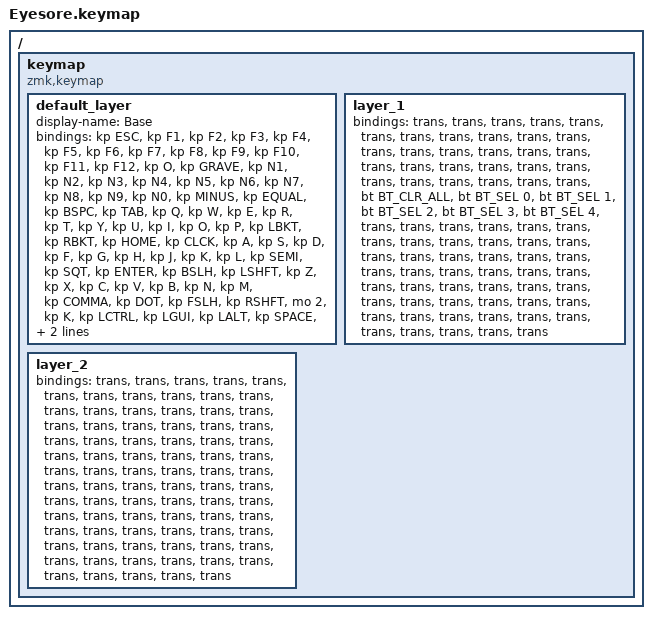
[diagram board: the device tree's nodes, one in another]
#include <behaviors.dtsi>
#include <dt-bindings/zmk/bt.h>
#include <dt-bindings/zmk/keys.h>

/ {
    keymap {
        compatible = "zmk,keymap";

        default_layer {
            display-name = "Base";
            bindings = <
&kp ESC  &kp F1  &kp F2  &kp F3  &kp F4  &kp F5  &kp F6  &kp F7  &kp F8  &kp F9  &kp F10  &kp F11  &kp F12  &kp O  &kp GRAVE  &kp N1  &kp N2  &kp N3  &kp N4  &kp N5  &kp N6  &kp N7  &kp N8  &kp N9  &kp N0  &kp MINUS  &kp EQUAL  &kp BSPC  &kp TAB  &kp Q  &kp W  &kp E  &kp R  &kp T  &kp Y  &kp U  &kp I  &kp O  &kp P  &kp LBKT  &kp RBKT  &kp HOME  &kp CLCK  &kp A  &kp S  &kp D  &kp F  &kp G  &kp H  &kp J  &kp K  &kp L  &kp SEMI  &kp SQT  &kp ENTER  &kp BSLH  &kp LSHFT  &kp Z  &kp X  &kp C  &kp V  &kp B  &kp N  &kp M  &kp COMMA  &kp DOT  &kp FSLH  &kp RSHFT  &mo 2  &kp K  &kp LCTRL  &kp LGUI  &kp LALT  &kp SPACE  &kp RALT  &kp Y  &kp RCTRL  &kp LEFT  &kp DOWN  &kp UP  &kp RIGHT  &mo 1
            >;
        };

        layer_1 {
            bindings = <
&trans  &trans  &trans  &trans  &trans  &trans  &trans  &trans  &trans  &trans  &trans  &trans  &trans  &trans  &trans  &trans  &trans  &trans  &trans  &trans  &trans  &trans  &trans  &trans  &trans  &trans  &trans  &trans  &trans  &bt BT_CLR_ALL  &bt BT_SEL 0  &bt BT_SEL 1  &bt BT_SEL 2  &bt BT_SEL 3  &bt BT_SEL 4  &trans  &trans  &trans  &trans  &trans  &trans  &trans  &trans  &trans  &trans  &trans  &trans  &trans  &trans  &trans  &trans  &trans  &trans  &trans  &trans  &trans  &trans  &trans  &trans  &trans  &trans  &trans  &trans  &trans  &trans  &trans  &trans  &trans  &trans  &trans  &trans  &trans  &trans  &trans  &trans  &trans  &trans  &trans  &trans  &trans  &trans  &trans
            >;
        };

        layer_2 {
            bindings = <
&trans  &trans  &trans  &trans  &trans  &trans  &trans  &trans  &trans  &trans  &trans  &trans  &trans  &trans  &trans  &trans  &trans  &trans  &trans  &trans  &trans  &trans  &trans  &trans  &trans  &trans  &trans  &trans  &trans  &trans  &trans  &trans  &trans  &trans  &trans  &trans  &trans  &trans  &trans  &trans  &trans  &trans  &trans  &trans  &trans  &trans  &trans  &trans  &trans  &trans  &trans  &trans  &trans  &trans  &trans  &trans  &trans  &trans  &trans  &trans  &trans  &trans  &trans  &trans  &trans  &trans  &trans  &trans  &trans  &trans  &trans  &trans  &trans  &trans  &trans  &trans  &trans  &trans  &trans  &trans  &trans  &trans
            >;
        };
    };
};
